VERSION ""

NS_ :

BS_:

BU_: BMS Third_Party_Device

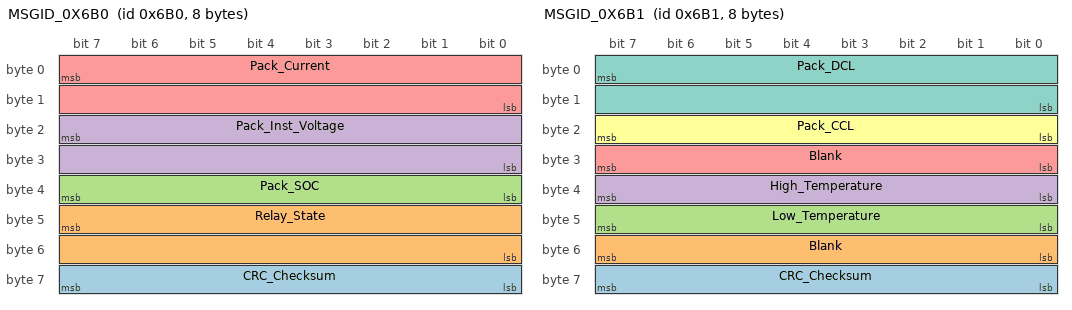
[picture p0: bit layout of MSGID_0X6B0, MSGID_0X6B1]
BO_ 1712 MSGID_0X6B0: 8 BMS
 SG_ CRC_Checksum : 63|8@0+ (1,1720) [1720|1975] ""  Third_Party_Device
 SG_ Relay_State : 47|16@0+ (1,0) [0|65535] ""  Third_Party_Device
 SG_ Pack_SOC : 39|8@0+ (0.5,0) [0|127.5] "%"  Third_Party_Device
 SG_ Pack_Inst_Voltage : 23|16@0+ (0.1,0) [0|6553.5] "V"  Third_Party_Device
 SG_ Pack_Current : 7|16@0+ (0.1,0) [0|6553.5] "A"  Third_Party_Device

BO_ 1713 MSGID_0X6B1: 8 BMS
 SG_ CRC_Checksum : 63|8@0+ (1,1721) [1721|1976] ""  Third_Party_Device
 SG_ Blank : 55|8@0+ (1,0) [0|255] ""  Third_Party_Device
 SG_ Low_Temperature : 47|8@0+ (1,0) [0|255] "C"  Third_Party_Device
 SG_ High_Temperature : 39|8@0+ (1,0) [0|255] "C"  Third_Party_Device
 SG_ Blank : 31|8@0+ (1,0) [0|255] ""  Third_Party_Device
 SG_ Pack_CCL : 23|8@0+ (1,0) [0|255] "A"  Third_Party_Device
 SG_ Pack_DCL : 7|16@0+ (1,0) [0|65535] "A"  Third_Party_Device

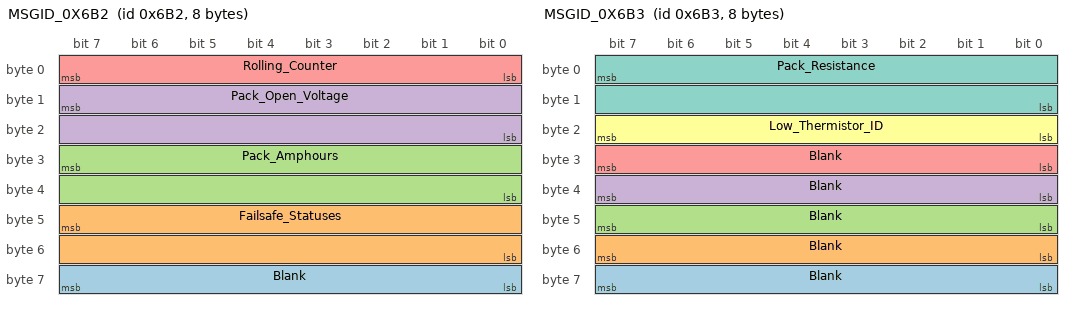
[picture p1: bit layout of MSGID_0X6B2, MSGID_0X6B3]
BO_ 1714 MSGID_0X6B2: 8 BMS
 SG_ Blank : 63|8@0+ (1,0) [0|255] ""  Third_Party_Device
 SG_ Failsafe_Statuses : 47|16@0+ (1,0) [0|65535] ""  Third_Party_Device
 SG_ Pack_Amphours : 31|16@0+ (0.1,0) [0|6553.5] "A.h"  Third_Party_Device
 SG_ Pack_Open_Voltage : 15|16@0+ (0.1,0) [0|6553.5] "V"  Third_Party_Device
 SG_ Rolling_Counter : 7|8@0+ (1,0) [0|255] ""  Third_Party_Device

BO_ 1715 MSGID_0X6B3: 8 BMS
 SG_ Blank : 63|8@0+ (1,0) [0|255] ""  Third_Party_Device
 SG_ Blank : 55|8@0+ (1,0) [0|255] ""  Third_Party_Device
 SG_ Blank : 47|8@0+ (1,0) [0|255] ""  Third_Party_Device
 SG_ Blank : 39|8@0+ (1,0) [0|255] ""  Third_Party_Device
 SG_ Blank : 31|8@0+ (1,0) [0|255] ""  Third_Party_Device
 SG_ Low_Thermistor_ID : 23|8@0+ (1,0) [0|255] ""  Third_Party_Device
 SG_ Pack_Resistance : 7|16@0+ (0.001,0) [0|65.535] "ohm"  Third_Party_Device

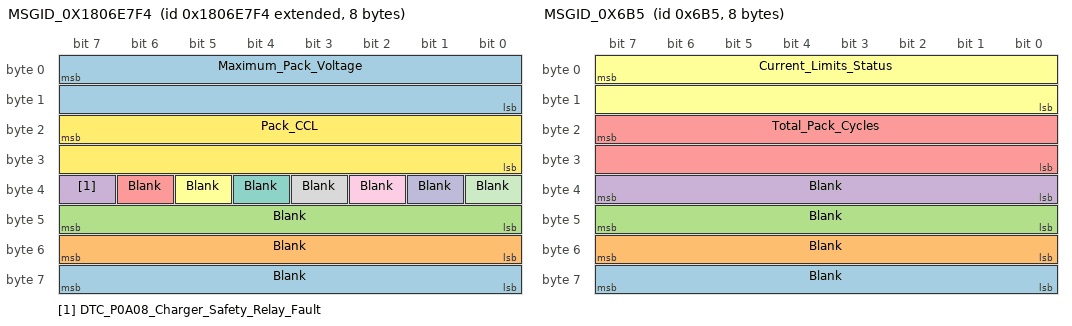
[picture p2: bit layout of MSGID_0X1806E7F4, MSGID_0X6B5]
BO_ 2550589428 MSGID_0X1806E7F4: 8 BMS
 SG_ Blank : 63|8@0+ (1,0) [0|255] ""  Third_Party_Device
 SG_ Blank : 55|8@0+ (1,0) [0|255] ""  Third_Party_Device
 SG_ Blank : 47|8@0+ (0.1,0) [0|25.5] ""  Third_Party_Device
 SG_ DTC_P0A08_Charger_Safety_Relay_Fault : 39|1@0- (1,0) [0|1] ""  Third_Party_Device
 SG_ Blank : 38|1@0- (1,0) [0|1] ""  Third_Party_Device
 SG_ Blank : 37|1@0- (1,0) [0|1] ""  Third_Party_Device
 SG_ Blank : 36|1@0- (1,0) [0|1] ""  Third_Party_Device
 SG_ Blank : 35|1@0- (1,0) [0|1] ""  Third_Party_Device
 SG_ Blank : 34|1@0- (1,0) [0|1] ""  Third_Party_Device
 SG_ Blank : 33|1@0- (1,0) [0|1] ""  Third_Party_Device
 SG_ Blank : 32|1@0- (1,0) [0|1] ""  Third_Party_Device
 SG_ Pack_CCL : 23|16@0+ (0.1,0) [0|6553.5] "A"  Third_Party_Device
 SG_ Maximum_Pack_Voltage : 7|16@0+ (0.1,0) [0|6553.5] "V"  Third_Party_Device

BO_ 1717 MSGID_0X6B5: 8 BMS
 SG_ Blank : 63|8@0+ (1,0) [0|255] ""  Third_Party_Device
 SG_ Blank : 55|8@0+ (1,0) [0|255] ""  Third_Party_Device
 SG_ Blank : 47|8@0+ (1,0) [0|255] ""  Third_Party_Device
 SG_ Blank : 39|8@0+ (1,0) [0|255] ""  Third_Party_Device
 SG_ Total_Pack_Cycles : 23|16@0+ (1,0) [0|65535] ""  Third_Party_Device
 SG_ Current_Limits_Status : 7|16@0+ (1,0) [0|65535] ""  Third_Party_Device

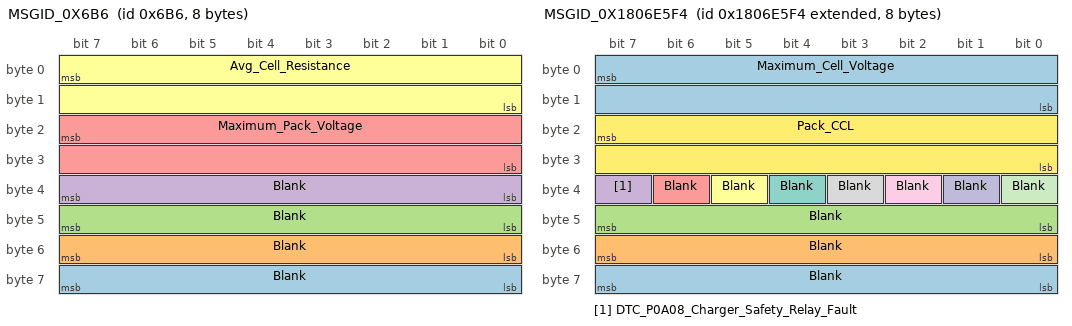
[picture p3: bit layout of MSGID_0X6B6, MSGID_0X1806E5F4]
BO_ 1718 MSGID_0X6B6: 8 BMS
 SG_ Blank : 63|8@0+ (1,0) [0|255] ""  Third_Party_Device
 SG_ Blank : 55|8@0+ (1,0) [0|255] ""  Third_Party_Device
 SG_ Blank : 47|8@0+ (1,0) [0|255] ""  Third_Party_Device
 SG_ Blank : 39|8@0+ (1,0) [0|255] ""  Third_Party_Device
 SG_ Maximum_Pack_Voltage : 23|16@0+ (0.1,0) [0|6553.5] "V"  Third_Party_Device
 SG_ Avg_Cell_Resistance : 7|16@0+ (0.01,0) [0|655.35] "mohm"  Third_Party_Device

BO_ 2550588916 MSGID_0X1806E5F4: 8 BMS
 SG_ Blank : 63|8@0+ (1,0) [0|255] ""  Third_Party_Device
 SG_ Blank : 55|8@0+ (1,0) [0|255] ""  Third_Party_Device
 SG_ Blank : 47|8@0+ (0.1,0) [0|25.5] ""  Third_Party_Device
 SG_ DTC_P0A08_Charger_Safety_Relay_Fault : 39|1@0- (1,0) [0|1] ""  Third_Party_Device
 SG_ Blank : 38|1@0- (1,0) [0|1] ""  Third_Party_Device
 SG_ Blank : 37|1@0- (1,0) [0|1] ""  Third_Party_Device
 SG_ Blank : 36|1@0- (1,0) [0|1] ""  Third_Party_Device
 SG_ Blank : 35|1@0- (1,0) [0|1] ""  Third_Party_Device
 SG_ Blank : 34|1@0- (1,0) [0|1] ""  Third_Party_Device
 SG_ Blank : 33|1@0- (1,0) [0|1] ""  Third_Party_Device
 SG_ Blank : 32|1@0- (1,0) [0|1] ""  Third_Party_Device
 SG_ Pack_CCL : 23|16@0+ (0.1,0) [0|6553.5] "A"  Third_Party_Device
 SG_ Maximum_Cell_Voltage : 7|16@0+ (0.1,0) [0|6553.5] "V"  Third_Party_Device

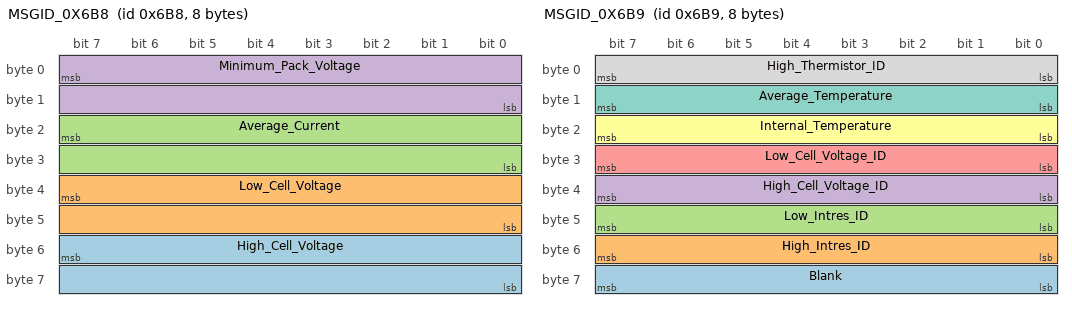
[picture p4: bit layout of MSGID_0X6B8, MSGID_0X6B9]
BO_ 1720 MSGID_0X6B8: 8 BMS
 SG_ High_Cell_Voltage : 55|16@0+ (0.0001,0) [0|6.5535] "V"  Third_Party_Device
 SG_ Low_Cell_Voltage : 39|16@0+ (0.0001,0) [0|6.5535] "V"  Third_Party_Device
 SG_ Average_Current : 23|16@0+ (0.1,0) [0|6553.5] "A"  Third_Party_Device
 SG_ Minimum_Pack_Voltage : 7|16@0+ (0.1,0) [0|6553.5] "V"  Third_Party_Device

BO_ 1721 MSGID_0X6B9: 8 BMS
 SG_ Blank : 63|8@0+ (1,0) [0|255] ""  Third_Party_Device
 SG_ High_Intres_ID : 55|8@0+ (1,0) [0|255] ""  Third_Party_Device
 SG_ Low_Intres_ID : 47|8@0+ (1,0) [0|255] ""  Third_Party_Device
 SG_ High_Cell_Voltage_ID : 39|8@0+ (1,0) [0|255] ""  Third_Party_Device
 SG_ Low_Cell_Voltage_ID : 31|8@0+ (1,0) [0|255] ""  Third_Party_Device
 SG_ Internal_Temperature : 23|8@0+ (1,0) [0|255] "C"  Third_Party_Device
 SG_ Average_Temperature : 15|8@0+ (1,0) [0|255] "C"  Third_Party_Device
 SG_ High_Thermistor_ID : 7|8@0+ (1,0) [0|255] ""  Third_Party_Device

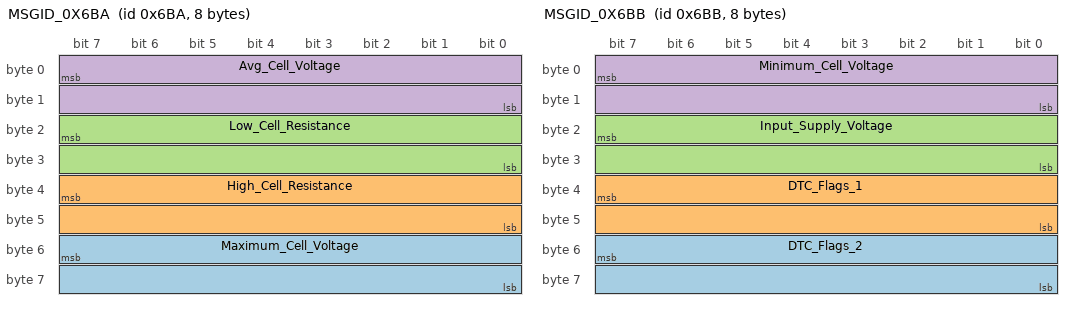
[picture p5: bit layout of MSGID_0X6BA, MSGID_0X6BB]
BO_ 1722 MSGID_0X6BA: 8 BMS
 SG_ Maximum_Cell_Voltage : 55|16@0+ (0.0001,0) [0|6.5535] "V"  Third_Party_Device
 SG_ High_Cell_Resistance : 39|16@0+ (0.01,0) [0|655.35] "mohm"  Third_Party_Device
 SG_ Low_Cell_Resistance : 23|16@0+ (0.01,0) [0|655.35] "mohm"  Third_Party_Device
 SG_ Avg_Cell_Voltage : 7|16@0+ (0.0001,0) [0|6.5535] "V"  Third_Party_Device

BO_ 1723 MSGID_0X6BB: 8 BMS
 SG_ DTC_Flags_2 : 55|16@0+ (1,0) [0|65535] ""  Third_Party_Device
 SG_ DTC_Flags_1 : 39|16@0+ (1,0) [0|65535] ""  Third_Party_Device
 SG_ Input_Supply_Voltage : 23|16@0+ (0.1,0) [0|6553.5] "V"  Third_Party_Device
 SG_ Minimum_Cell_Voltage : 7|16@0+ (0.0001,0) [0|6.5535] "V"  Third_Party_Device

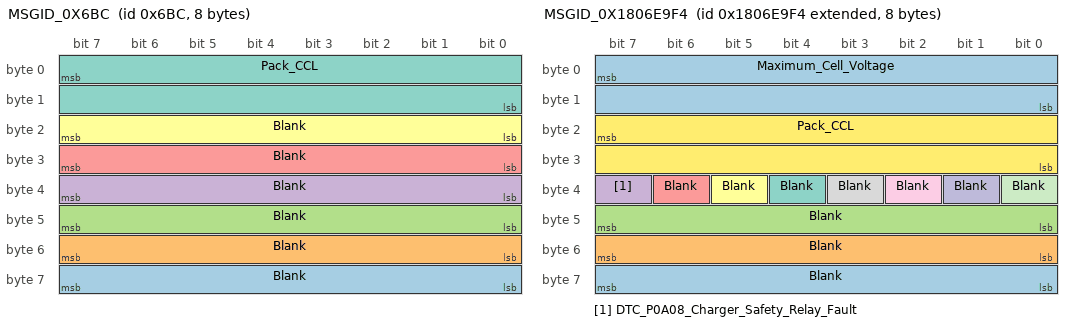
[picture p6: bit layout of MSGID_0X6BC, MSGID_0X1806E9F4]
BO_ 1724 MSGID_0X6BC: 8 BMS
 SG_ Blank : 63|8@0+ (1,0) [0|255] ""  Third_Party_Device
 SG_ Blank : 55|8@0+ (1,0) [0|255] ""  Third_Party_Device
 SG_ Blank : 47|8@0+ (1,0) [0|255] ""  Third_Party_Device
 SG_ Blank : 39|8@0+ (1,0) [0|255] ""  Third_Party_Device
 SG_ Blank : 31|8@0+ (1,0) [0|255] ""  Third_Party_Device
 SG_ Blank : 23|8@0+ (1,0) [0|255] ""  Third_Party_Device
 SG_ Pack_CCL : 7|16@0+ (1,0) [0|65535] "A"  Third_Party_Device

BO_ 2550589940 MSGID_0X1806E9F4: 8 BMS
 SG_ Blank : 63|8@0+ (1,0) [0|255] ""  Third_Party_Device
 SG_ Blank : 55|8@0+ (1,0) [0|255] ""  Third_Party_Device
 SG_ Blank : 47|8@0+ (1,0) [0|255] ""  Third_Party_Device
 SG_ DTC_P0A08_Charger_Safety_Relay_Fault : 39|1@0- (1,0) [0|1] ""  Third_Party_Device
 SG_ Blank : 38|1@0- (1,0) [0|1] ""  Third_Party_Device
 SG_ Blank : 37|1@0- (1,0) [0|1] ""  Third_Party_Device
 SG_ Blank : 36|1@0- (1,0) [0|1] ""  Third_Party_Device
 SG_ Blank : 35|1@0- (1,0) [0|1] ""  Third_Party_Device
 SG_ Blank : 34|1@0- (1,0) [0|1] ""  Third_Party_Device
 SG_ Blank : 33|1@0- (1,0) [0|1] ""  Third_Party_Device
 SG_ Blank : 32|1@0- (1,0) [0|1] ""  Third_Party_Device
 SG_ Pack_CCL : 23|16@0+ (0.1,0) [0|6553.5] "A"  Third_Party_Device
 SG_ Maximum_Cell_Voltage : 7|16@0+ (0.1,0) [0|6553.5] "V"  Third_Party_Device

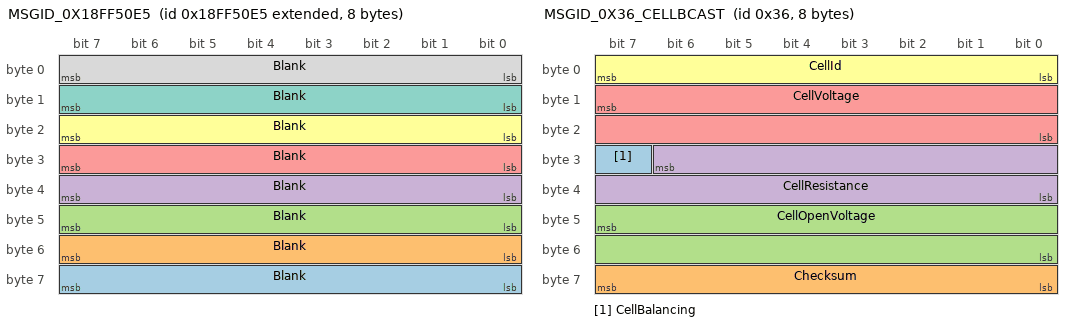
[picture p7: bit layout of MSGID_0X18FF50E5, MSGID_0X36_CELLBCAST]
BO_ 2566869221 MSGID_0X18FF50E5: 8 Third_Party_Device
 SG_ Blank : 63|8@0+ (1,0) [0|255] ""  BMS
 SG_ Blank : 55|8@0+ (1,0) [0|255] ""  BMS
 SG_ Blank : 47|8@0+ (1,0) [0|255] ""  BMS
 SG_ Blank : 39|8@0+ (1,0) [0|255] ""  BMS
 SG_ Blank : 31|8@0+ (1,0) [0|255] ""  BMS
 SG_ Blank : 23|8@0+ (1,0) [0|255] ""  BMS
 SG_ Blank : 15|8@0+ (1,0) [0|255] ""  BMS
 SG_ Blank : 7|8@0+ (1,0) [0|255] ""  BMS

BO_ 54 MSGID_0X36_CELLBCAST: 8 BMS
 SG_ CellBalancing : 31|1@0- (1,0) [0|1] ""  Third_Party_Device
 SG_ Checksum : 63|8@0+ (1,0) [0|255] ""  Third_Party_Device
 SG_ CellOpenVoltage : 47|16@0+ (0.0001,0) [0|6.5535] "V"  Third_Party_Device
 SG_ CellResistance : 30|15@0+ (0.01,0) [0|327.67] "mohm"  Third_Party_Device
 SG_ CellVoltage : 15|16@0+ (0.0001,0) [0|6.5535] "V"  Third_Party_Device
 SG_ CellId : 7|8@0+ (1,0) [0|255] ""  Third_Party_Device

CM_ BO_ 1712 "This ID Transmits at 8 ms.";
CM_ BO_ 1713 "This ID Transmits at 104 ms.";
CM_ BO_ 1714 "This ID Transmits at 96 ms.";
CM_ BO_ 1715 "This ID Transmits at 16 ms.";
CM_ BO_ 2550589428 "This ID Transmits at 808 ms.";
CM_ BO_ 1717 "This ID Transmits at 496 ms.";
CM_ BO_ 1718 "This ID Transmits at 8 ms.";
CM_ BO_ 2550588916 "This ID Transmits at 808 ms.";
CM_ BO_ 1720 "This ID Transmits at 8 ms.";
CM_ BO_ 1721 "This ID Transmits at 8 ms.";
CM_ BO_ 1722 "This ID Transmits at 8 ms.";
CM_ BO_ 1723 "This ID Transmits at 8 ms.";
CM_ BO_ 1724 "This ID Transmits at 8 ms.";
CM_ BO_ 2550589940 "This ID Transmits at 808 ms.";
CM_ BO_ 54 "This ID Transmits at 4 ms.";
CM_ SG_ 54 Checksum "Value = (0x36 + 8 + byte0 + byte1 + ... + byte6) & 0xFF";
